AUTOSAR XML (schema 00044)
package /ComponentTypes
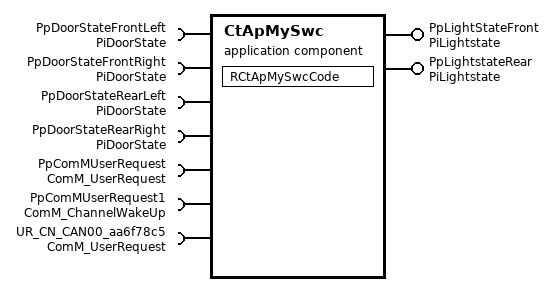
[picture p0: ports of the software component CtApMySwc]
  application sw component type CtApMySwc
    provide port PpLightStateFront: nonqueued-sender-com-spec{data-element=DeLightstate, init-value=constant-reference=Clightoff}, provided-interface=PiLightstate
    4 x require port, all with required-interface=PiDoorState:
      PpDoorStateFrontLeft: nonqueued-receiver-com-spec{data-element=DeDoorState, init-value=constant-reference=CDoorClosed}
      PpDoorStateFrontRight: nonqueued-receiver-com-spec{data-element=DeDoorState, init-value=constant-reference=CDoorClosed}
      PpDoorStateRearLeft: nonqueued-receiver-com-spec{data-element=DeDoorState, init-value=0}
      PpDoorStateRearRight: nonqueued-receiver-com-spec{data-element=DeDoorState, init-value=0}
    provide port PpLightstateRear: nonqueued-sender-com-spec{data-element=DeLightstate, init-value=0}, provided-interface=PiLightstate
    require port PpComMUserRequest: required-com-specs=[RequestComMode, GetCurrentComMode, GetMaxComMode, GetRequestedComMode], required-interface=ComM_UserRequest
    require port PpComMUserRequest1: required-com-specs=[PreventWakeUp, GetInhibitionStatus], required-interface=ComM_ChannelWakeUp
    require port UR_CN_CAN00_aa6f78c5: required-com-specs=[RequestComMode, GetCurrentComMode, GetMaxComMode, GetRequestedComMode], required-interface=ComM_UserRequest
    behavior CtApMySwc_InternalBehavior: data-type-mapping=DemoTypeMapping
      4 x data received event, all with start-on-event=RCtApMySwcCode:
        DRT_RCtApMySwcCode_PpDoorStateFrontLeft_DeDoorState: data=PpDoorStateFrontLeft.DeDoorState
        DRT_RCtApMySwcCode_PpDoorStateFrontRight_DeDoorState: data=PpDoorStateFrontRight.DeDoorState
        DRT_RCtApMySwcCode_PpDoorStateRearLeft_DeDoorState: data=PpDoorStateRearLeft.DeDoorState
        DRT_RCtApMySwcCode_PpDoorStateRearRight_DeDoorState: data=PpDoorStateRearRight.DeDoorState
      runnable RCtApMySwcCode
        data-read-access:
          access READ_PpDoorStateRearLeft_DeDoorState: accessed-variable=PpDoorStateRearLeft.DeDoorState
        data-receive-point-by-arguments:
          access REC_PpDoorStateRearRight_DeDoorState: accessed-variable=PpDoorStateRearRight.DeDoorState
          access REC_PpDoorStateFrontLeft_DeDoorState: accessed-variable=PpDoorStateFrontLeft.DeDoorState
          access REC_PpDoorStateFrontRight_DeDoorState: accessed-variable=PpDoorStateFrontRight.DeDoorState
        data-send-points:
          access SEND_PpLightStateFront_DeLightstate: accessed-variable=PpLightStateFront.DeLightstate
          access SEND_PpLightstateRear_DeLightstate: accessed-variable=PpLightstateRear.DeLightstate
        sync call SC_PpComMUserRequest_RequestComMode: operation=PpComMUserRequest.RequestComMode
        sync call SC_PpComMUserRequest_GetRequestedComMode: operation=PpComMUserRequest.GetRequestedComMode
  swc implementation CtApMySwc_Implementation: behavior=CtApMySwc_InternalBehavior
